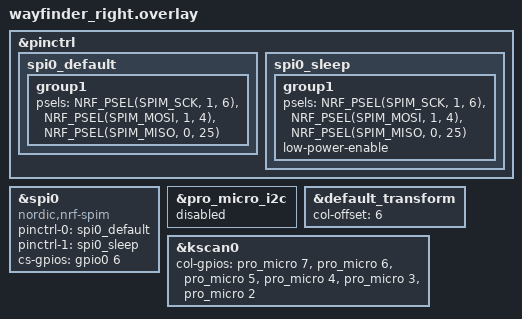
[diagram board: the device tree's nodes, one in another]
#include "wayfinder.dtsi"

&pinctrl {
    spi0_default: spi0_default {
        group1 {
            psels = <NRF_PSEL(SPIM_SCK, 1, 6)>,
                    <NRF_PSEL(SPIM_MOSI, 1, 4)>,
                    <NRF_PSEL(SPIM_MISO, 0, 25)>;
        };
    };
    spi0_sleep: spi0_sleep {
        group1 {
            psels = <NRF_PSEL(SPIM_SCK, 1, 6)>,
                    <NRF_PSEL(SPIM_MOSI, 1, 4)>,
                    <NRF_PSEL(SPIM_MISO, 0, 25)>;
            low-power-enable;
        };
    };
};

nice_view_spi: &spi0 {
    compatible = "nordic,nrf-spim";
    pinctrl-0 = <&spi0_default>;
    pinctrl-1 = <&spi0_sleep>;
    pinctrl-names = "default", "sleep";
    cs-gpios = <&gpio0 6 GPIO_ACTIVE_HIGH>;
};

&pro_micro_i2c {
    status = "disabled";
};

&default_transform { 
    col-offset = <6>;
};

&kscan0 {
    col-gpios
        = <&pro_micro 7 GPIO_ACTIVE_HIGH>
        , <&pro_micro 6 GPIO_ACTIVE_HIGH>
        , <&pro_micro 5 GPIO_ACTIVE_HIGH>
        , <&pro_micro 4 GPIO_ACTIVE_HIGH>
        , <&pro_micro 3 GPIO_ACTIVE_HIGH>
        , <&pro_micro 2 GPIO_ACTIVE_HIGH>
        ;
};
